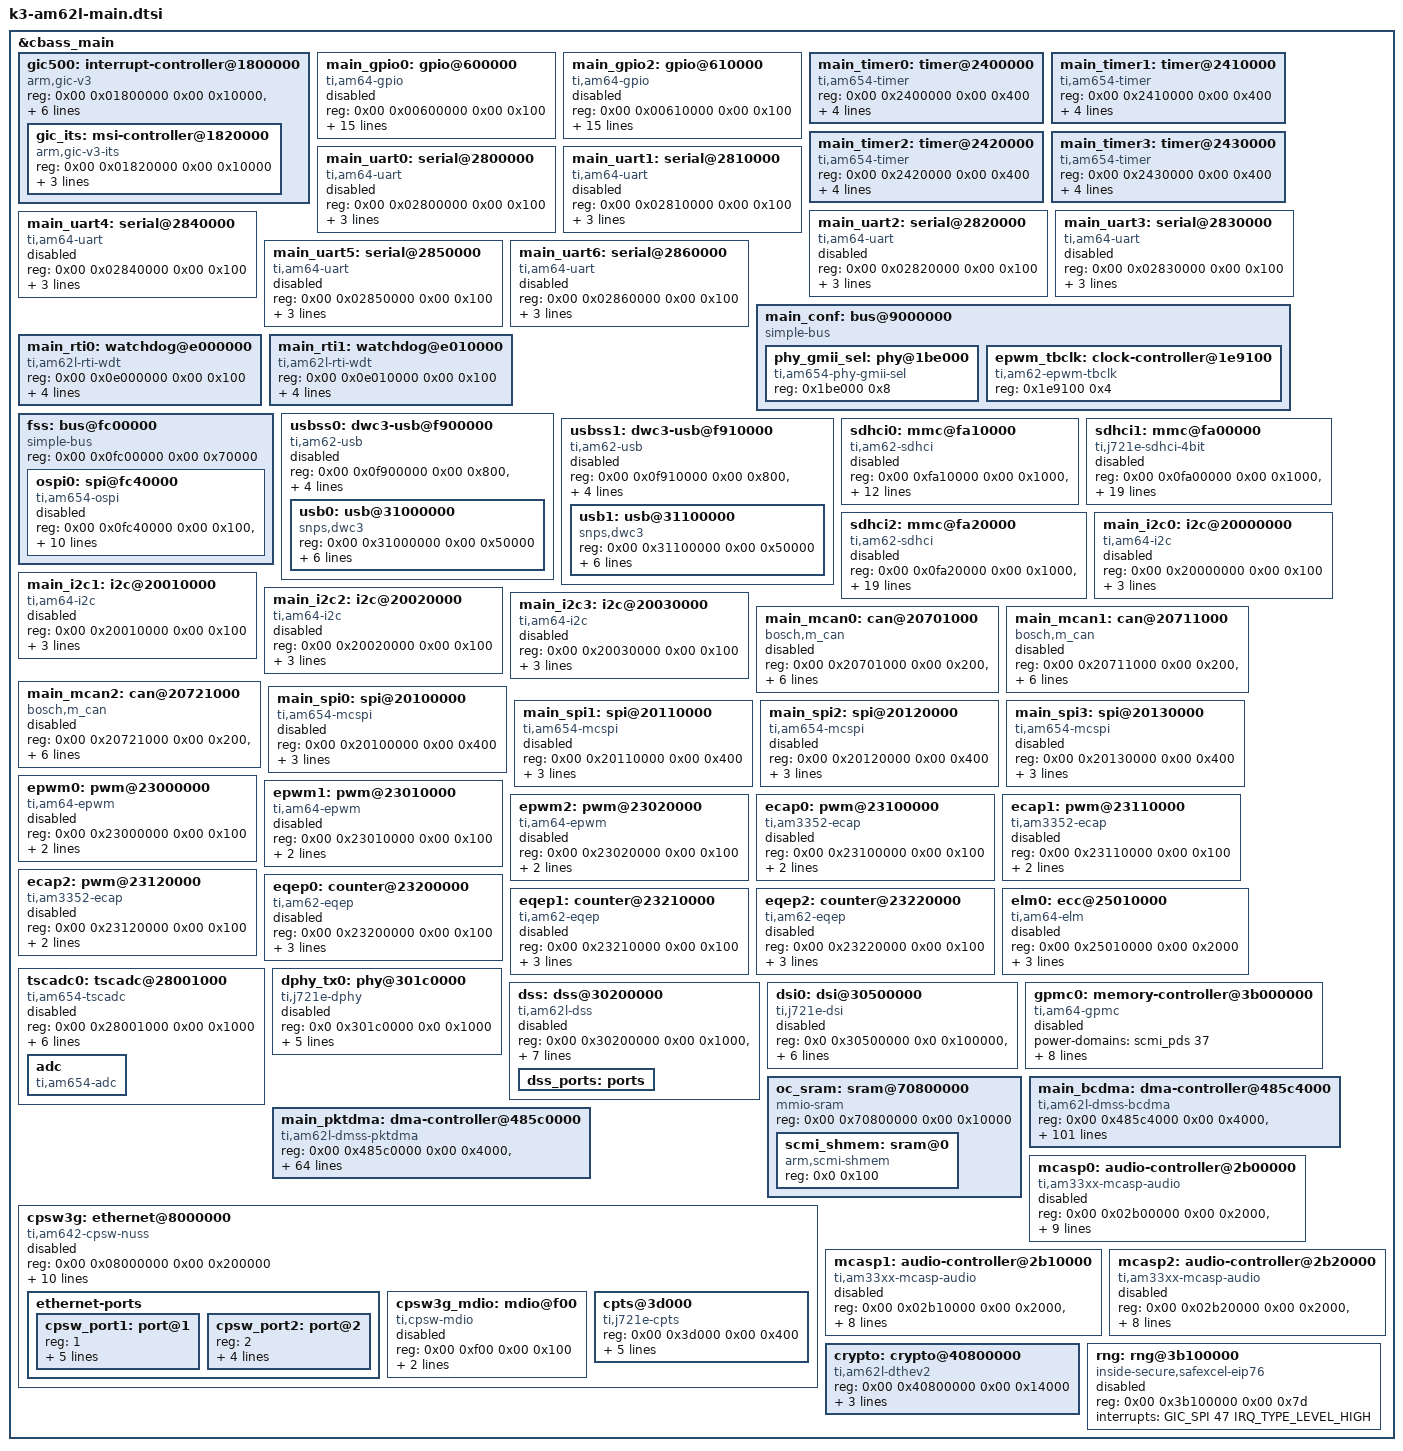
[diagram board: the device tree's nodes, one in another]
// SPDX-License-Identifier: GPL-2.0-only or MIT
/*
 * Device Tree file for the AM62L main domain peripherals
 * Copyright (C) 2024 Texas Instruments Incorporated - https://www.ti.com/
 *
 * Technical Reference Manual: https://www.ti.com/lit/pdf/sprujb4
 */

&cbass_main {
	gic500: interrupt-controller@1800000 {
		compatible = "arm,gic-v3";
		reg = <0x00 0x01800000 0x00 0x10000>,	/* GICD */
		      <0x00 0x01840000 0x00 0xc0000>,	/* GICR */
		      <0x01 0x00000000 0x00 0x2000>,    /* GICC */
		      <0x01 0x00010000 0x00 0x1000>,    /* GICH */
		      <0x01 0x00020000 0x00 0x2000>;    /* GICV */
		ranges;
		#address-cells = <2>;
		#size-cells = <2>;
		#interrupt-cells = <3>;
		interrupt-controller;
		/*
		 * vcpumntirq:
		 * virtual CPU interface maintenance interrupt
		 */
		interrupts = <GIC_PPI 9 IRQ_TYPE_LEVEL_HIGH>;

		gic_its: msi-controller@1820000 {
			compatible = "arm,gic-v3-its";
			reg = <0x00 0x01820000 0x00 0x10000>;
			socionext,synquacer-pre-its = <0x1000000 0x400000>;
			msi-controller;
			#msi-cells = <1>;
		};
	};

	main_gpio0: gpio@600000 {
		compatible = "ti,am64-gpio", "ti,keystone-gpio";
		reg = <0x00 0x00600000 0x00 0x100>;
		gpio-controller;
		#gpio-cells = <2>;
		interrupt-parent = <&gic500>;
		interrupts = <GIC_SPI 260 IRQ_TYPE_EDGE_RISING>, <GIC_SPI 261 IRQ_TYPE_EDGE_RISING>,
			     <GIC_SPI 262 IRQ_TYPE_EDGE_RISING>, <GIC_SPI 263 IRQ_TYPE_EDGE_RISING>,
			     <GIC_SPI 264 IRQ_TYPE_EDGE_RISING>, <GIC_SPI 265 IRQ_TYPE_EDGE_RISING>,
			     <GIC_SPI 266 IRQ_TYPE_EDGE_RISING>, <GIC_SPI 267 IRQ_TYPE_EDGE_RISING>;
		interrupt-controller;
		#interrupt-cells = <2>;
		ti,ngpio = <126>;
		ti,davinci-gpio-unbanked = <0>;
		power-domains = <&scmi_pds 34>;
		clocks = <&scmi_clk 140>;
		clock-names = "gpio";
		status = "disabled";
	};

	main_gpio2: gpio@610000 {
		compatible = "ti,am64-gpio", "ti,keystone-gpio";
		reg = <0x00 0x00610000 0x00 0x100>;
		gpio-controller;
		#gpio-cells = <2>;
		interrupt-parent = <&gic500>;
		interrupts = <GIC_SPI 280 IRQ_TYPE_EDGE_RISING>, <GIC_SPI 281 IRQ_TYPE_EDGE_RISING>,
			     <GIC_SPI 282 IRQ_TYPE_EDGE_RISING>, <GIC_SPI 283 IRQ_TYPE_EDGE_RISING>,
			     <GIC_SPI 284 IRQ_TYPE_EDGE_RISING>, <GIC_SPI 285 IRQ_TYPE_EDGE_RISING>,
			     <GIC_SPI 286 IRQ_TYPE_EDGE_RISING>, <GIC_SPI 287 IRQ_TYPE_EDGE_RISING>;
		interrupt-controller;
		#interrupt-cells = <2>;
		ti,ngpio = <79>;
		ti,davinci-gpio-unbanked = <0>;
		power-domains = <&scmi_pds 35>;
		clocks = <&scmi_clk 141>;
		clock-names = "gpio";
		status = "disabled";
	};

	main_timer0: timer@2400000 {
		compatible = "ti,am654-timer";
		reg = <0x00 0x2400000 0x00 0x400>;
		interrupts = <GIC_SPI 170 IRQ_TYPE_LEVEL_HIGH>;
		clocks = <&scmi_clk 58>;
		clock-names = "fck";
		power-domains = <&scmi_pds 15>;
		ti,timer-pwm;
	};

	main_timer1: timer@2410000 {
		compatible = "ti,am654-timer";
		reg = <0x00 0x2410000 0x00 0x400>;
		interrupts = <GIC_SPI 171 IRQ_TYPE_LEVEL_HIGH>;
		clocks = <&scmi_clk 63>;
		clock-names = "fck";
		power-domains = <&scmi_pds 16>;
		ti,timer-pwm;
	};

	main_timer2: timer@2420000 {
		compatible = "ti,am654-timer";
		reg = <0x00 0x2420000 0x00 0x400>;
		interrupts = <GIC_SPI 172 IRQ_TYPE_LEVEL_HIGH>;
		clocks = <&scmi_clk 77>;
		clock-names = "fck";
		power-domains = <&scmi_pds 17>;
		ti,timer-pwm;
	};

	main_timer3: timer@2430000 {
		compatible = "ti,am654-timer";
		reg = <0x00 0x2430000 0x00 0x400>;
		interrupts = <GIC_SPI 173 IRQ_TYPE_LEVEL_HIGH>;
		clocks = <&scmi_clk 82>;
		clock-names = "fck";
		power-domains = <&scmi_pds 18>;
		ti,timer-pwm;
	};

	main_uart0: serial@2800000 {
		compatible = "ti,am64-uart", "ti,am654-uart";
		reg = <0x00 0x02800000 0x00 0x100>;
		interrupts = <GIC_SPI 96 IRQ_TYPE_LEVEL_HIGH>;
		power-domains = <&scmi_pds 89>;
		clocks = <&scmi_clk 358>;
		clock-names = "fclk";
		status = "disabled";
	};

	main_uart1: serial@2810000 {
		compatible = "ti,am64-uart", "ti,am654-uart";
		reg = <0x00 0x02810000 0x00 0x100>;
		interrupts = <GIC_SPI 97 IRQ_TYPE_LEVEL_HIGH>;
		power-domains = <&scmi_pds 77>;
		clocks = <&scmi_clk 312>;
		clock-names = "fclk";
		status = "disabled";
	};

	main_uart2: serial@2820000 {
		compatible = "ti,am64-uart", "ti,am654-uart";
		reg = <0x00 0x02820000 0x00 0x100>;
		interrupts = <GIC_SPI 98 IRQ_TYPE_LEVEL_HIGH>;
		power-domains = <&scmi_pds 78>;
		clocks = <&scmi_clk 314>;
		clock-names = "fclk";
		status = "disabled";
	};

	main_uart3: serial@2830000 {
		compatible = "ti,am64-uart", "ti,am654-uart";
		reg = <0x00 0x02830000 0x00 0x100>;
		interrupts = <GIC_SPI 99 IRQ_TYPE_LEVEL_HIGH>;
		power-domains = <&scmi_pds 79>;
		clocks = <&scmi_clk 316>;
		clock-names = "fclk";
		status = "disabled";
	};

	main_uart4: serial@2840000 {
		compatible = "ti,am64-uart", "ti,am654-uart";
		reg = <0x00 0x02840000 0x00 0x100>;
		interrupts = <GIC_SPI 100 IRQ_TYPE_LEVEL_HIGH>;
		power-domains = <&scmi_pds 80>;
		clocks = <&scmi_clk 318>;
		clock-names = "fclk";
		status = "disabled";
	};

	main_uart5: serial@2850000 {
		compatible = "ti,am64-uart", "ti,am654-uart";
		reg = <0x00 0x02850000 0x00 0x100>;
		interrupts = <GIC_SPI 101 IRQ_TYPE_LEVEL_HIGH>;
		power-domains = <&scmi_pds 81>;
		clocks = <&scmi_clk 320>;
		clock-names = "fclk";
		status = "disabled";
	};

	main_uart6: serial@2860000 {
		compatible = "ti,am64-uart", "ti,am654-uart";
		reg = <0x00 0x02860000 0x00 0x100>;
		interrupts = <GIC_SPI 102 IRQ_TYPE_LEVEL_HIGH>;
		power-domains = <&scmi_pds 82>;
		clocks = <&scmi_clk 322>;
		clock-names = "fclk";
		status = "disabled";
	};

	main_conf: bus@9000000 {
		compatible = "simple-bus";
		#address-cells = <1>;
		#size-cells = <1>;
		ranges = <0x0 0x00 0x09000000 0x400000>;

		phy_gmii_sel: phy@1be000 {
			compatible = "ti,am654-phy-gmii-sel";
			reg = <0x1be000 0x8>;
			#phy-cells = <1>;
		};

		epwm_tbclk: clock-controller@1e9100 {
			compatible = "ti,am62-epwm-tbclk";
			reg = <0x1e9100 0x4>;
			#clock-cells = <1>;
		};
	};

	main_rti0: watchdog@e000000 {
		compatible = "ti,am62l-rti-wdt";
		reg = <0x00 0x0e000000 0x00 0x100>;
		clocks = <&scmi_clk 277>;
		power-domains = <&scmi_pds 60>;
		assigned-clocks = <&scmi_clk 277>;
		assigned-clock-parents = <&scmi_clk 274>;
	};

	main_rti1: watchdog@e010000 {
		compatible = "ti,am62l-rti-wdt";
		reg = <0x00 0x0e010000 0x00 0x100>;
		clocks = <&scmi_clk 283>;
		power-domains = <&scmi_pds 61>;
		assigned-clocks = <&scmi_clk 283>;
		assigned-clock-parents = <&scmi_clk 280>;
	};

	fss: bus@fc00000 {
		compatible = "simple-bus";
		reg = <0x00 0x0fc00000 0x00 0x70000>;
		#address-cells = <2>;
		#size-cells = <2>;
		ranges;

		ospi0: spi@fc40000 {
			compatible = "ti,am654-ospi", "cdns,qspi-nor";
			reg = <0x00 0x0fc40000 0x00 0x100>,
			      <0x05 0x00000000 0x01 0x00000000>;
			interrupts = <GIC_SPI 240 IRQ_TYPE_LEVEL_HIGH>;
			cdns,fifo-depth = <256>;
			cdns,fifo-width = <4>;
			cdns,trigger-address = <0x0>;
			cdns,phase-detect-selector = <2>;
			clocks = <&scmi_clk 136>;
			assigned-clocks = <&scmi_clk 136>;
			assigned-clock-rates = <166666666>;
			power-domains = <&scmi_pds 32>;
			#address-cells = <1>;
			#size-cells = <0>;
			status = "disabled";
		};
	};

	usbss0: dwc3-usb@f900000 {
		compatible = "ti,am62-usb";
		reg = <0x00 0x0f900000 0x00 0x800>,
		      <0x00 0x0f908000 0x00 0x400>;
		clocks = <&scmi_clk 331>;
		clock-names = "ref";
		ti,syscon-phy-pll-refclk = <&usb0_phy_ctrl 0x0>;
		#address-cells = <2>;
		#size-cells = <2>;
		power-domains = <&scmi_pds 95>;
		ranges;
		status = "disabled";

		usb0: usb@31000000 {
			compatible = "snps,dwc3";
			reg = <0x00 0x31000000 0x00 0x50000>;
			interrupts = <GIC_SPI 215 IRQ_TYPE_LEVEL_HIGH>, /* irq.0 */
				     <GIC_SPI 215 IRQ_TYPE_LEVEL_HIGH>; /* irq.0 */
			interrupt-names = "host", "peripheral";
			maximum-speed = "high-speed";
			dr_mode = "otg";
			bootph-all;
			snps,usb2-gadget-lpm-disable;
			snps,usb2-lpm-disable;
		};
	};

	usbss1: dwc3-usb@f910000 {
		compatible = "ti,am62-usb";
		reg = <0x00 0x0f910000 0x00 0x800>,
		      <0x00 0x0f918000 0x00 0x400>;
		clocks = <&scmi_clk 338>;
		clock-names = "ref";
		ti,syscon-phy-pll-refclk = <&usb1_phy_ctrl 0x0>;
		#address-cells = <2>;
		#size-cells = <2>;
		power-domains = <&scmi_pds 96>;
		ranges;
		status = "disabled";

		usb1: usb@31100000 {
			compatible = "snps,dwc3";
			reg = <0x00 0x31100000 0x00 0x50000>;
			interrupts = <GIC_SPI 225 IRQ_TYPE_LEVEL_HIGH>, /* irq.0 */
				     <GIC_SPI 225 IRQ_TYPE_LEVEL_HIGH>; /* irq.0 */
			interrupt-names = "host", "peripheral";
			maximum-speed = "high-speed";
			dr_mode = "otg";
			snps,usb2-gadget-lpm-disable;
			snps,usb2-lpm-disable;
		};
	};

	sdhci0: mmc@fa10000 {
		compatible = "ti,am62-sdhci";
		reg = <0x00 0xfa10000 0x00 0x1000>, <0x00 0xfa18000 0x00 0x400>;
		interrupts = <GIC_SPI 239 IRQ_TYPE_LEVEL_HIGH>;
		power-domains = <&scmi_pds 28>;
		clocks = <&scmi_clk 122>, <&scmi_clk 125>;
		clock-names = "clk_ahb", "clk_xin";
		assigned-clocks = <&scmi_clk 125>;
		assigned-clock-parents = <&scmi_clk 124>;
		bus-width = <8>;
		mmc-hs200-1_8v;
		ti,clkbuf-sel = <0x7>;
		ti,otap-del-sel-legacy = <0x0>;
		ti,otap-del-sel-mmc-hs = <0x0>;
		ti,otap-del-sel-hs200 = <0x6>;
		status = "disabled";
	};

	sdhci1: mmc@fa00000 {
		compatible = "ti,j721e-sdhci-4bit";
		reg = <0x00 0x0fa00000 0x00 0x1000>, <0x00 0x0fa08000 0x00 0x400>;
		interrupts = <GIC_SPI 237 IRQ_TYPE_LEVEL_HIGH>;
		power-domains = <&scmi_pds 26>;
		clocks = <&scmi_clk 106>, <&scmi_clk 109>;
		clock-names = "clk_ahb", "clk_xin";
		assigned-clocks = <&scmi_clk 109>;
		assigned-clock-parents = <&scmi_clk 108>;
		bus-width = <4>;
		ti,clkbuf-sel = <0x7>;
		ti,otap-del-sel-legacy = <0x0>;
		ti,otap-del-sel-sd-hs = <0x0>;
		ti,otap-del-sel-sdr12 = <0xf>;
		ti,otap-del-sel-sdr25 = <0xf>;
		ti,otap-del-sel-sdr50 = <0xc>;
		ti,otap-del-sel-sdr104 = <0x6>;
		ti,otap-del-sel-ddr50 = <0x9>;
		ti,itap-del-sel-legacy = <0x0>;
		ti,itap-del-sel-sd-hs = <0x0>;
		ti,itap-del-sel-sdr12 = <0x0>;
		ti,itap-del-sel-sdr25 = <0x0>;
		status = "disabled";
	};

	sdhci2: mmc@fa20000 {
		compatible = "ti,am62-sdhci";
		reg = <0x00 0x0fa20000 0x00 0x1000>, <0x00 0x0fa28000 0x00 0x400>;
		interrupts = <GIC_SPI 238 IRQ_TYPE_LEVEL_HIGH>;
		power-domains = <&scmi_pds 27>;
		clocks = <&scmi_clk 114>, <&scmi_clk 117>;
		clock-names = "clk_ahb", "clk_xin";
		assigned-clocks = <&scmi_clk 117>;
		assigned-clock-parents = <&scmi_clk 116>;
		bus-width = <4>;
		ti,clkbuf-sel = <0x7>;
		ti,otap-del-sel-legacy = <0x0>;
		ti,otap-del-sel-sd-hs = <0x0>;
		ti,otap-del-sel-sdr12 = <0xf>;
		ti,otap-del-sel-sdr25 = <0xf>;
		ti,otap-del-sel-sdr50 = <0xc>;
		ti,otap-del-sel-sdr104 = <0x6>;
		ti,otap-del-sel-ddr50 = <0x9>;
		ti,itap-del-sel-legacy = <0x0>;
		ti,itap-del-sel-sd-hs = <0x0>;
		ti,itap-del-sel-sdr12 = <0x0>;
		ti,itap-del-sel-sdr25 = <0x0>;
		status = "disabled";
	};

	main_i2c0: i2c@20000000 {
		compatible = "ti,am64-i2c", "ti,omap4-i2c";
		reg = <0x00 0x20000000 0x00 0x100>;
		interrupts = <GIC_SPI 64 IRQ_TYPE_LEVEL_HIGH>;
		#address-cells = <1>;
		#size-cells = <0>;
		power-domains = <&scmi_pds 53>;
		clocks = <&scmi_clk 246>;
		clock-names = "fck";
		status = "disabled";
	};

	main_i2c1: i2c@20010000 {
		compatible = "ti,am64-i2c", "ti,omap4-i2c";
		reg = <0x00 0x20010000 0x00 0x100>;
		interrupts = <GIC_SPI 65 IRQ_TYPE_LEVEL_HIGH>;
		#address-cells = <1>;
		#size-cells = <0>;
		power-domains = <&scmi_pds 54>;
		clocks = <&scmi_clk 250>;
		clock-names = "fck";
		status = "disabled";
	};

	main_i2c2: i2c@20020000 {
		compatible = "ti,am64-i2c", "ti,omap4-i2c";
		reg = <0x00 0x20020000 0x00 0x100>;
		interrupts = <GIC_SPI 66 IRQ_TYPE_LEVEL_HIGH>;
		#address-cells = <1>;
		#size-cells = <0>;
		power-domains = <&scmi_pds 55>;
		clocks = <&scmi_clk 254>;
		clock-names = "fck";
		status = "disabled";
	};

	main_i2c3: i2c@20030000 {
		compatible = "ti,am64-i2c", "ti,omap4-i2c";
		reg = <0x00 0x20030000 0x00 0x100>;
		interrupts = <GIC_SPI 67 IRQ_TYPE_LEVEL_HIGH>;
		#address-cells = <1>;
		#size-cells = <0>;
		power-domains = <&scmi_pds 56>;
		clocks = <&scmi_clk 258>;
		clock-names = "fck";
		status = "disabled";
	};

	main_mcan0: can@20701000 {
		compatible = "bosch,m_can";
		reg = <0x00 0x20701000 0x00 0x200>,
		      <0x00 0x20708000 0x00 0x8000>;
		reg-names = "m_can", "message_ram";
		power-domains = <&scmi_pds 47>;
		clocks = <&scmi_clk 179>, <&scmi_clk 178>;
		clock-names = "hclk", "cclk";
		interrupts = <GIC_SPI 113 IRQ_TYPE_LEVEL_HIGH>,
			     <GIC_SPI 114 IRQ_TYPE_LEVEL_HIGH>;
		interrupt-names = "int0", "int1";
		bosch,mram-cfg = <0x0 128 64 64 64 64 32 32>;
		status = "disabled";
	};

	main_mcan1: can@20711000 {
		compatible = "bosch,m_can";
		reg = <0x00 0x20711000 0x00 0x200>,
		      <0x00 0x20718000 0x00 0x8000>;
		reg-names = "m_can", "message_ram";
		power-domains = <&scmi_pds 48>;
		clocks = <&scmi_clk 185>, <&scmi_clk 184>;
		clock-names = "hclk", "cclk";
		interrupts = <GIC_SPI 116 IRQ_TYPE_LEVEL_HIGH>,
			     <GIC_SPI 117 IRQ_TYPE_LEVEL_HIGH>;
		interrupt-names = "int0", "int1";
		bosch,mram-cfg = <0x0 128 64 64 64 64 32 32>;
		status = "disabled";
	};

	main_mcan2: can@20721000 {
		compatible = "bosch,m_can";
		reg = <0x00 0x20721000 0x00 0x200>,
		      <0x00 0x20728000 0x00 0x8000>;
		reg-names = "m_can", "message_ram";
		power-domains = <&scmi_pds 49>;
		clocks = <&scmi_clk 191>, <&scmi_clk 190>;
		clock-names = "hclk", "cclk";
		interrupts = <GIC_SPI 119 IRQ_TYPE_LEVEL_HIGH>,
			     <GIC_SPI 120 IRQ_TYPE_LEVEL_HIGH>;
		interrupt-names = "int0", "int1";
		bosch,mram-cfg = <0x0 128 64 64 64 64 32 32>;
		status = "disabled";
	};

	main_spi0: spi@20100000 {
		compatible = "ti,am654-mcspi", "ti,omap4-mcspi";
		reg = <0x00 0x20100000 0x00 0x400>;
		interrupts = <GIC_SPI 80 IRQ_TYPE_LEVEL_HIGH>;
		#address-cells = <1>;
		#size-cells = <0>;
		power-domains = <&scmi_pds 72>;
		clocks = <&scmi_clk 299>;
		status = "disabled";
	};

	main_spi1: spi@20110000 {
		compatible = "ti,am654-mcspi","ti,omap4-mcspi";
		reg = <0x00 0x20110000 0x00 0x400>;
		interrupts = <GIC_SPI 81 IRQ_TYPE_LEVEL_HIGH>;
		#address-cells = <1>;
		#size-cells = <0>;
		power-domains = <&scmi_pds 73>;
		clocks = <&scmi_clk 302>;
		status = "disabled";
	};

	main_spi2: spi@20120000 {
		compatible = "ti,am654-mcspi","ti,omap4-mcspi";
		reg = <0x00 0x20120000 0x00 0x400>;
		interrupts = <GIC_SPI 82 IRQ_TYPE_LEVEL_HIGH>;
		#address-cells = <1>;
		#size-cells = <0>;
		power-domains = <&scmi_pds 74>;
		clocks = <&scmi_clk 305>;
		status = "disabled";
	};

	main_spi3: spi@20130000 {
		compatible = "ti,am654-mcspi","ti,omap4-mcspi";
		reg = <0x00 0x20130000 0x00 0x400>;
		interrupts = <GIC_SPI 83 IRQ_TYPE_LEVEL_HIGH>;
		#address-cells = <1>;
		#size-cells = <0>;
		power-domains = <&scmi_pds 75>;
		clocks = <&scmi_clk 308>;
		status = "disabled";
	};

	epwm0: pwm@23000000 {
		compatible = "ti,am64-epwm", "ti,am3352-ehrpwm";
		#pwm-cells = <3>;
		reg = <0x00 0x23000000 0x00 0x100>;
		power-domains = <&scmi_pds 40>;
		clocks = <&epwm_tbclk 0>, <&scmi_clk 164>;
		clock-names = "tbclk", "fck";
		status = "disabled";
	};

	epwm1: pwm@23010000 {
		compatible = "ti,am64-epwm", "ti,am3352-ehrpwm";
		#pwm-cells = <3>;
		reg = <0x00 0x23010000 0x00 0x100>;
		power-domains = <&scmi_pds 41>;
		clocks = <&epwm_tbclk 1>, <&scmi_clk 165>;
		clock-names = "tbclk", "fck";
		status = "disabled";
	};

	epwm2: pwm@23020000 {
		compatible = "ti,am64-epwm", "ti,am3352-ehrpwm";
		#pwm-cells = <3>;
		reg = <0x00 0x23020000 0x00 0x100>;
		power-domains = <&scmi_pds 42>;
		clocks = <&epwm_tbclk 2>, <&scmi_clk 166>;
		clock-names = "tbclk", "fck";
		status = "disabled";
	};

	ecap0: pwm@23100000 {
		compatible = "ti,am3352-ecap";
		#pwm-cells = <3>;
		reg = <0x00 0x23100000 0x00 0x100>;
		power-domains = <&scmi_pds 23>;
		clocks = <&scmi_clk 99>;
		clock-names = "fck";
		status = "disabled";
	};

	ecap1: pwm@23110000 {
		compatible = "ti,am3352-ecap";
		#pwm-cells = <3>;
		reg = <0x00 0x23110000 0x00 0x100>;
		power-domains = <&scmi_pds 24>;
		clocks = <&scmi_clk 100>;
		clock-names = "fck";
		status = "disabled";
	};

	ecap2: pwm@23120000 {
		compatible = "ti,am3352-ecap";
		#pwm-cells = <3>;
		reg = <0x00 0x23120000 0x00 0x100>;
		power-domains = <&scmi_pds 25>;
		clocks = <&scmi_clk 101>;
		clock-names = "fck";
		status = "disabled";
	};

	eqep0: counter@23200000 {
		compatible = "ti,am62-eqep";
		reg = <0x00 0x23200000 0x00 0x100>;
		power-domains = <&scmi_pds 29>;
		clocks = <&scmi_clk 127>;
		interrupts = <GIC_SPI 162 IRQ_TYPE_EDGE_RISING>;
		status = "disabled";
	};

	eqep1: counter@23210000 {
		compatible = "ti,am62-eqep";
		reg = <0x00 0x23210000 0x00 0x100>;
		power-domains = <&scmi_pds 30>;
		clocks = <&scmi_clk 128>;
		interrupts = <GIC_SPI 163 IRQ_TYPE_EDGE_RISING>;
		status = "disabled";
	};

	eqep2: counter@23220000 {
		compatible = "ti,am62-eqep";
		reg = <0x00 0x23220000 0x00 0x100>;
		power-domains = <&scmi_pds 31>;
		clocks = <&scmi_clk 129>;
		interrupts = <GIC_SPI 164 IRQ_TYPE_EDGE_RISING>;
		status = "disabled";
	};

	elm0: ecc@25010000 {
		compatible = "ti,am64-elm";
		reg = <0x00 0x25010000 0x00 0x2000>;
		interrupts = <GIC_SPI 243 IRQ_TYPE_LEVEL_HIGH>;
		power-domains = <&scmi_pds 25>;
		clocks = <&scmi_clk 102>;
		clock-names = "fck";
		status = "disabled";
	};

	tscadc0: tscadc@28001000 {
		compatible = "ti,am654-tscadc", "ti,am3359-tscadc";
		reg = <0x00 0x28001000 0x00 0x1000>;
		interrupts = <GIC_SPI 253 IRQ_TYPE_LEVEL_HIGH>;
		power-domains = <&scmi_pds 0>;
		clocks = <&scmi_clk 4>;
		assigned-clocks = <&scmi_clk 4>;
		assigned-clock-parents = <&scmi_clk 2>;
		assigned-clock-rates = <60000000>;
		clock-names = "fck";
		status = "disabled";

		adc {
			#io-channel-cells = <1>;
			compatible = "ti,am654-adc", "ti,am3359-adc";
		};
	};

	dphy_tx0: phy@301c0000 {
		compatible = "ti,j721e-dphy";
		reg = <0x0 0x301c0000 0x0 0x1000>;
		clocks = <&scmi_clk 348>, <&scmi_clk 343>;
		clock-names = "psm", "pll_ref";
		#phy-cells = <0>;
		power-domains = <&scmi_pds 86>;
		assigned-clocks = <&scmi_clk 343>;
		assigned-clock-parents = <&scmi_clk 341>;
		assigned-clock-rates = <25000000>;
		status = "disabled";
		bootph-all;
	};

	dss: dss@30200000 {
		compatible = "ti,am62l-dss";
		reg = <0x00 0x30200000 0x00 0x1000>, /* common */
		      <0x00 0x30202000 0x00 0x1000>, /* vidl1 */
		      <0x00 0x30207000 0x00 0x1000>, /* ovr1 */
		      <0x00 0x3020a000 0x00 0x1000>, /* vp1 */
		      <0x00 0x30201000 0x00 0x1000>; /* common1 */
		reg-names = "common", "vidl1", "ovr1", "vp1", "common1";
		power-domains = <&scmi_pds 39>;
		clocks = <&scmi_clk 162>,
			 <&scmi_clk 161>;
		clock-names = "fck", "vp1";
		interrupts = <GIC_SPI 60 IRQ_TYPE_LEVEL_HIGH>;
		status = "disabled";
		bootph-all;

		dss_ports: ports {
			#address-cells = <1>;
			#size-cells = <0>;
		};
	};

	dsi0: dsi@30500000 {
		compatible = "ti,j721e-dsi";
		reg = <0x0 0x30500000 0x0 0x100000>, <0x0 0x30270000 0x0 0x100>;
		clocks = <&scmi_clk 155>, <&scmi_clk 158>;
		clock-names = "dsi_p_clk", "dsi_sys_clk";
		power-domains = <&scmi_pds 38>;
		interrupt-parent = <&gic500>;
		interrupts = <GIC_SPI 57 IRQ_TYPE_LEVEL_HIGH>;
		phys = <&dphy_tx0>;
		phy-names = "dphy";
		status = "disabled";
		bootph-all;
	};

	gpmc0: memory-controller@3b000000 {
		compatible = "ti,am64-gpmc";
		power-domains = <&scmi_pds 37>;
		clocks = <&scmi_clk 149>;
		clock-names = "fck";
		reg = <0x00 0x3b000000 0x00 0x400>,
		      <0x00 0x50000000 0x00 0x8000000>;
		reg-names = "cfg", "data";
		interrupts = <GIC_SPI 244 IRQ_TYPE_LEVEL_HIGH>;
		gpmc,num-cs = <3>;
		gpmc,num-waitpins = <2>;
		#address-cells = <2>;
		#size-cells = <1>;
		interrupt-controller;
		#interrupt-cells = <2>;
		gpio-controller;
		#gpio-cells = <2>;
		status = "disabled";
	};

	oc_sram: sram@70800000 {
		compatible = "mmio-sram";
		reg = <0x00 0x70800000 0x00 0x10000>;
		ranges = <0x0 0x00 0x70800000 0x10000>;
		#address-cells = <1>;
		#size-cells = <1>;

		scmi_shmem: sram@0 {
			compatible = "arm,scmi-shmem";
			reg = <0x0 0x100>;
			bootph-all;
		};
	};

	main_bcdma: dma-controller@485c4000 {
		compatible = "ti,am62l-dmss-bcdma";
		reg = <0x00 0x485c4000 0x00 0x4000>,
			<0x00 0x48880000 0x00 0x10000>,
			<0x00 0x48800000 0x00 0x80000>,
			<0x00 0x47000000 0x00 0x200000>;
		reg-names = "gcfg", "bchanrt", "chanrt", "ringrt";
		#address-cells = <2>;
		#interrupt-cells = <1>;
		#dma-cells = <4>;
		interrupt-map = <0 0 0 &gic500 0 0 GIC_SPI 352 IRQ_TYPE_LEVEL_HIGH>,
			<0 0 1 &gic500 0 0 GIC_SPI 353 IRQ_TYPE_LEVEL_HIGH>,
			<0 0 2 &gic500 0 0 GIC_SPI 356 IRQ_TYPE_LEVEL_HIGH>,
			<0 0 3 &gic500 0 0 GIC_SPI 357 IRQ_TYPE_LEVEL_HIGH>,
			<0 0 4 &gic500 0 0 GIC_SPI 360 IRQ_TYPE_LEVEL_HIGH>,
			<0 0 5 &gic500 0 0 GIC_SPI 361 IRQ_TYPE_LEVEL_HIGH>,
			<0 0 6 &gic500 0 0 GIC_SPI 364 IRQ_TYPE_LEVEL_HIGH>,
			<0 0 7 &gic500 0 0 GIC_SPI 365 IRQ_TYPE_LEVEL_HIGH>,
			<0 0 8 &gic500 0 0 GIC_SPI 368 IRQ_TYPE_LEVEL_HIGH>,
			<0 0 9 &gic500 0 0 GIC_SPI 369 IRQ_TYPE_LEVEL_HIGH>,
			<0 0 10 &gic500 0 0 GIC_SPI 372 IRQ_TYPE_LEVEL_HIGH>,
			<0 0 11 &gic500 0 0 GIC_SPI 373 IRQ_TYPE_LEVEL_HIGH>,
			<0 0 12 &gic500 0 0 GIC_SPI 376 IRQ_TYPE_LEVEL_HIGH>,
			<0 0 13 &gic500 0 0 GIC_SPI 377 IRQ_TYPE_LEVEL_HIGH>,
			<0 0 16 &gic500 0 0 GIC_SPI 320 IRQ_TYPE_LEVEL_HIGH>,
			<0 0 17 &gic500 0 0 GIC_SPI 321 IRQ_TYPE_LEVEL_HIGH>,
			<0 0 24 &gic500 0 0 GIC_SPI 324 IRQ_TYPE_LEVEL_HIGH>,
			<0 0 25 &gic500 0 0 GIC_SPI 325 IRQ_TYPE_LEVEL_HIGH>,
			<0 0 32 &gic500 0 0 GIC_SPI 328 IRQ_TYPE_LEVEL_HIGH>,
			<0 0 33 &gic500 0 0 GIC_SPI 329 IRQ_TYPE_LEVEL_HIGH>,
			<0 0 40 &gic500 0 0 GIC_SPI 332 IRQ_TYPE_LEVEL_HIGH>,
			<0 0 41 &gic500 0 0 GIC_SPI 333 IRQ_TYPE_LEVEL_HIGH>,
			<0 0 48 &gic500 0 0 GIC_SPI 384 IRQ_TYPE_LEVEL_HIGH>,
			<0 0 49 &gic500 0 0 GIC_SPI 385 IRQ_TYPE_LEVEL_HIGH>,
			<0 0 50 &gic500 0 0 GIC_SPI 386 IRQ_TYPE_LEVEL_HIGH>,
			<0 0 51 &gic500 0 0 GIC_SPI 387 IRQ_TYPE_LEVEL_HIGH>,
			<0 0 52 &gic500 0 0 GIC_SPI 388 IRQ_TYPE_LEVEL_HIGH>,
			<0 0 53 &gic500 0 0 GIC_SPI 389 IRQ_TYPE_LEVEL_HIGH>,
			<0 0 64 &gic500 0 0 GIC_SPI 52 IRQ_TYPE_LEVEL_HIGH>,
			<0 0 65 &gic500 0 0 GIC_SPI 49 IRQ_TYPE_LEVEL_HIGH>,
			<0 0 66 &gic500 0 0 GIC_SPI 50 IRQ_TYPE_LEVEL_HIGH>,
			<0 0 80 &gic500 0 0 GIC_SPI 482 IRQ_TYPE_LEVEL_HIGH>,
			<0 0 67 &gic500 0 0 GIC_SPI 548 IRQ_TYPE_LEVEL_HIGH>,
			<0 0 128 &gic500 0 0 GIC_SPI 516 IRQ_TYPE_LEVEL_HIGH>,
			<0 0 129 &gic500 0 0 GIC_SPI 517 IRQ_TYPE_LEVEL_HIGH>,
			<0 0 130 &gic500 0 0 GIC_SPI 518 IRQ_TYPE_LEVEL_HIGH>,
			<0 0 131 &gic500 0 0 GIC_SPI 519 IRQ_TYPE_LEVEL_HIGH>,
			<0 0 132 &gic500 0 0 GIC_SPI 520 IRQ_TYPE_LEVEL_HIGH>,
			<0 0 133 &gic500 0 0 GIC_SPI 521 IRQ_TYPE_LEVEL_HIGH>,
			<0 0 134 &gic500 0 0 GIC_SPI 522 IRQ_TYPE_LEVEL_HIGH>,
			<0 0 135 &gic500 0 0 GIC_SPI 523 IRQ_TYPE_LEVEL_HIGH>,
			<0 0 136 &gic500 0 0 GIC_SPI 524 IRQ_TYPE_LEVEL_HIGH>,
			<0 0 137 &gic500 0 0 GIC_SPI 525 IRQ_TYPE_LEVEL_HIGH>,
			<0 0 138 &gic500 0 0 GIC_SPI 526 IRQ_TYPE_LEVEL_HIGH>,
			<0 0 139 &gic500 0 0 GIC_SPI 527 IRQ_TYPE_LEVEL_HIGH>,
			<0 0 140 &gic500 0 0 GIC_SPI 528 IRQ_TYPE_LEVEL_HIGH>,
			<0 0 141 &gic500 0 0 GIC_SPI 529 IRQ_TYPE_LEVEL_HIGH>,
			<0 0 142 &gic500 0 0 GIC_SPI 530 IRQ_TYPE_LEVEL_HIGH>,
			<0 0 143 &gic500 0 0 GIC_SPI 531 IRQ_TYPE_LEVEL_HIGH>;
	};

	main_pktdma: dma-controller@485c0000 {
		compatible = "ti,am62l-dmss-pktdma";
		reg = <0x00 0x485c0000 0x00 0x4000>,
			<0x00 0x48900000 0x00 0x80000>,
			<0x00 0x47200000 0x00 0x100000>;
		reg-names = "gcfg", "chanrt", "ringrt";
		#address-cells = <2>;
		#dma-cells = <2>;
		#interrupt-cells = <1>;
		interrupt-map = <0 0 0 &gic500 0 0 GIC_SPI 354 IRQ_TYPE_LEVEL_HIGH>,
			<0 0 1 &gic500 0 0 GIC_SPI 355 IRQ_TYPE_LEVEL_HIGH>,
			<0 0 2 &gic500 0 0 GIC_SPI 358 IRQ_TYPE_LEVEL_HIGH>,
			<0 0 3 &gic500 0 0 GIC_SPI 359 IRQ_TYPE_LEVEL_HIGH>,
			<0 0 4 &gic500 0 0 GIC_SPI 362 IRQ_TYPE_LEVEL_HIGH>,
			<0 0 5 &gic500 0 0 GIC_SPI 363 IRQ_TYPE_LEVEL_HIGH>,
			<0 0 6 &gic500 0 0 GIC_SPI 366 IRQ_TYPE_LEVEL_HIGH>,
			<0 0 7 &gic500 0 0 GIC_SPI 367 IRQ_TYPE_LEVEL_HIGH>,
			<0 0 8 &gic500 0 0 GIC_SPI 370 IRQ_TYPE_LEVEL_HIGH>,
			<0 0 9 &gic500 0 0 GIC_SPI 371 IRQ_TYPE_LEVEL_HIGH>,
			<0 0 10 &gic500 0 0 GIC_SPI 374 IRQ_TYPE_LEVEL_HIGH>,
			<0 0 11 &gic500 0 0 GIC_SPI 375 IRQ_TYPE_LEVEL_HIGH>,
			<0 0 12 &gic500 0 0 GIC_SPI 378 IRQ_TYPE_LEVEL_HIGH>,
			<0 0 13 &gic500 0 0 GIC_SPI 379 IRQ_TYPE_LEVEL_HIGH>,
			<0 0 64 &gic500 0 0 GIC_SPI 500 IRQ_TYPE_LEVEL_HIGH>,
			<0 0 65 &gic500 0 0 GIC_SPI 501 IRQ_TYPE_LEVEL_HIGH>,
			<0 0 66 &gic500 0 0 GIC_SPI 502 IRQ_TYPE_LEVEL_HIGH>,
			<0 0 67 &gic500 0 0 GIC_SPI 503 IRQ_TYPE_LEVEL_HIGH>,
			<0 0 68 &gic500 0 0 GIC_SPI 504 IRQ_TYPE_LEVEL_HIGH>,
			<0 0 69 &gic500 0 0 GIC_SPI 505 IRQ_TYPE_LEVEL_HIGH>,
			<0 0 70 &gic500 0 0 GIC_SPI 506 IRQ_TYPE_LEVEL_HIGH>,
			<0 0 71 &gic500 0 0 GIC_SPI 507 IRQ_TYPE_LEVEL_HIGH>,
			<0 0 72 &gic500 0 0 GIC_SPI 508 IRQ_TYPE_LEVEL_HIGH>,
			<0 0 73 &gic500 0 0 GIC_SPI 509 IRQ_TYPE_LEVEL_HIGH>,
			<0 0 74 &gic500 0 0 GIC_SPI 510 IRQ_TYPE_LEVEL_HIGH>,
			<0 0 75 &gic500 0 0 GIC_SPI 511 IRQ_TYPE_LEVEL_HIGH>,
			<0 0 76 &gic500 0 0 GIC_SPI 512 IRQ_TYPE_LEVEL_HIGH>,
			<0 0 77 &gic500 0 0 GIC_SPI 513 IRQ_TYPE_LEVEL_HIGH>,
			<0 0 78 &gic500 0 0 GIC_SPI 514 IRQ_TYPE_LEVEL_HIGH>,
			<0 0 79 &gic500 0 0 GIC_SPI 515 IRQ_TYPE_LEVEL_HIGH>,
			<0 0 96 &gic500 0 0 GIC_SPI 484 IRQ_TYPE_LEVEL_HIGH>;
	};

	cpsw3g: ethernet@8000000 {
		compatible = "ti,am642-cpsw-nuss";
		#address-cells = <2>;
		#size-cells = <2>;
		reg = <0x00 0x08000000 0x00 0x200000>;
		reg-names = "cpsw_nuss";
		ranges = <0x00 0x00 0x00 0x08000000 0x00 0x200000>;
		clocks = <&scmi_clk 9>;
		clock-names = "fck";
		power-domains = <&scmi_pds 3>;
		dmas = <&main_pktdma 0xc600 15>,
			   <&main_pktdma 0xc601 15>,
			   <&main_pktdma 0xc602 15>,
			   <&main_pktdma 0xc603 15>,
			   <&main_pktdma 0xc604 15>,
			   <&main_pktdma 0xc605 15>,
			   <&main_pktdma 0xc606 15>,
			   <&main_pktdma 0xc607 15>,
			   <&main_pktdma 0x4600 15>;
		dma-names = "tx0", "tx1", "tx2", "tx3", "tx4", "tx5", "tx6",
					"tx7", "rx";
		status = "disabled";

		ethernet-ports {
			#address-cells = <1>;
			#size-cells = <0>;

			cpsw_port1: port@1 {
				reg = <1>;
				ti,mac-only;
				label = "port1";
				phys = <&phy_gmii_sel 1>;
				ti,syscon-efuse = <&cpsw_mac_syscon 0x0>;
				mac-address = [00 00 00 00 00 00];
			};

			cpsw_port2: port@2 {
				reg = <2>;
				ti,mac-only;
				label = "port2";
				phys = <&phy_gmii_sel 2>;
				mac-address = [00 00 00 00 00 00];
			};
		};

		cpsw3g_mdio: mdio@f00 {
			compatible = "ti,cpsw-mdio","ti,davinci_mdio";
			reg = <0x00 0xf00 0x00 0x100>;
			#address-cells = <1>;
			#size-cells = <0>;
			clocks = <&scmi_clk 9>;
			clock-names = "fck";
			bus_freq = <1000000>;
			status = "disabled";
		};

		cpts@3d000 {
			compatible = "ti,j721e-cpts";
			reg = <0x00 0x3d000 0x00 0x400>;
			clocks = <&scmi_clk 10>;
			clock-names = "cpts";
			interrupts-extended = <&gic500 GIC_SPI 234 IRQ_TYPE_LEVEL_HIGH>;
			interrupt-names = "cpts";
			ti,cpts-ext-ts-inputs = <4>;
			ti,cpts-periodic-outputs = <2>;
		};
	};

	mcasp0: audio-controller@2b00000 {
		compatible = "ti,am33xx-mcasp-audio";
		reg = <0x00 0x02b00000 0x00 0x2000>,
				<0x00 0x02b08000 0x00 0x400>;
		reg-names = "mpu", "dat";
		interrupts = <GIC_SPI 246 IRQ_TYPE_LEVEL_HIGH>,
					<GIC_SPI 245 IRQ_TYPE_LEVEL_HIGH>;
		interrupt-names = "tx", "rx";

		clocks = <&scmi_clk 194>;
		clock-names = "fck";
		assigned-clocks = <&scmi_clk 194>;
		assigned-clock-parents = <&scmi_clk 193>;
		dmas = <&main_bcdma 0 0 0xc500 0>, <&main_bcdma 0 0 0x4500 0>;
		dma-names = "tx", "rx";
		power-domains = <&scmi_pds 50>;

		status = "disabled";
	};

	mcasp1: audio-controller@2b10000 {
		compatible = "ti,am33xx-mcasp-audio";
		reg = <0x00 0x02b10000 0x00 0x2000>,
				<0x00 0x02b18000 0x00 0x400>;
		reg-names = "mpu", "dat";
		interrupts = <GIC_SPI 248 IRQ_TYPE_LEVEL_HIGH>,
					<GIC_SPI 247 IRQ_TYPE_LEVEL_HIGH>;
		interrupt-names = "tx", "rx";

		clocks = <&scmi_clk 216>;
		clock-names = "fck";
		assigned-clocks = <&scmi_clk 216>;
		dmas = <&main_bcdma 0 0 0xc501 0>, <&main_bcdma 0 0 0x4501 0>;
		dma-names = "tx", "rx";
		power-domains = <&scmi_pds 51>;

		status = "disabled";
	};

	mcasp2: audio-controller@2b20000 {
		compatible = "ti,am33xx-mcasp-audio";
		reg = <0x00 0x02b20000 0x00 0x2000>,
				<0x00 0x02b28000 0x00 0x400>;
		reg-names = "mpu", "dat";
		interrupts = <GIC_SPI 250 IRQ_TYPE_LEVEL_HIGH>,
					<GIC_SPI 249 IRQ_TYPE_LEVEL_HIGH>;
		interrupt-names = "tx", "rx";

		clocks = <&scmi_clk 230>;
		clock-names = "fck";
		assigned-clocks = <&scmi_clk 230>;
		dmas = <&main_bcdma 0 0 0xc502 0>, <&main_bcdma 0 0 0x4502 0>;
		dma-names = "tx", "rx";
		power-domains = <&scmi_pds 52>;

		status = "disabled";
	};

	crypto: crypto@40800000 {
		compatible = "ti,am62l-dthev2";
		reg = <0x00 0x40800000 0x00 0x14000>;

		dmas = <&main_bcdma 0 0 0x4700 0>,
		       <&main_bcdma 0 0 0xc701 0>,
		       <&main_bcdma 0 0 0xc700 0>;
		dma-names = "rx", "tx1", "tx2";
	};

	rng: rng@3b100000 {
		compatible = "inside-secure,safexcel-eip76";
		reg = <0x00 0x3b100000 0x00 0x7d>;
		interrupts = <GIC_SPI 47 IRQ_TYPE_LEVEL_HIGH>;
		status = "reserved"; /* Reserved for OP-TEE */
	};
};
